# platform_designer_hps_system_hps_0_hps register map
Vendor: default_vendor.com; File version: 0.0
Registers are 32-bit, read-write, reset 0x0 unless marked. A register's access mark holds for its fields unless they carry their own. Offsets are from the block's base; [hi:lo] are bit positions; {n}, {i} and the like mark numbered series; 'fields as' and 'values as' point back to an identical list.

## usb0 (part 2 of 4) — Registers in the USB OTG Controller Module. Only the Core Global, Power and Clock Gating, Data FIFO Access, and Host Port registers can be accessedin both Host and Device modes. When the USB OTG Controller is operating in one mode, either Device or Host, the application must not access registers from the other mode. If an illegal access occurs, a Mode Mismatch interrupt is generated and reflected in the Core Interrupt register (GINTSTS.ModeMis). When the core switches from one mode to another, the registers in the new mode must be reprogrammed as they would be after a power-on reset. The register address map is fixed and does not depend on the module configuration (for example, how many endpoints are implemented). Host and Device mode registers occupy different addresses.
Base 0xFFB00000
Same registers: usb1 0xFFB40000
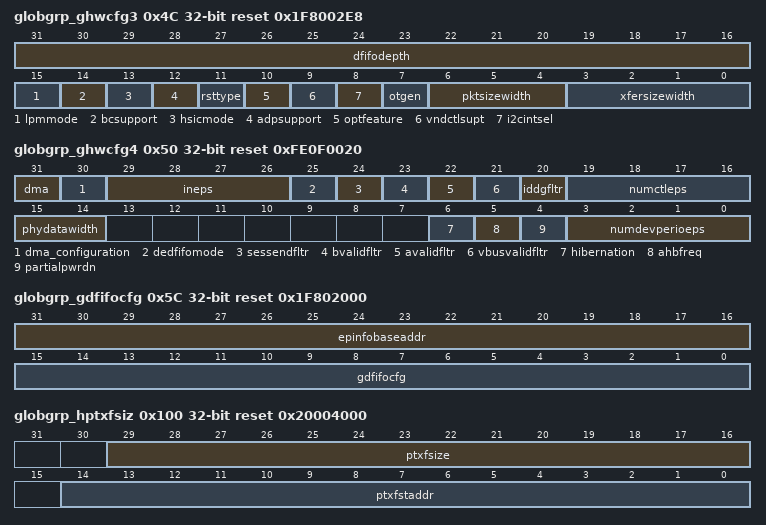
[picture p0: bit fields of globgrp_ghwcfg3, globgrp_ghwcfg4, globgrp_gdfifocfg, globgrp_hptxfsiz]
0x4C globgrp_ghwcfg3 ro reset 0x1F8002E8 — This register contains the configuration options.
  [31:16] dfifodepth — DFIFO Depth. This value is in terms of 35-bit words. Minimum value is 32 Maximum value is 8192
  [15] lpmmode — LPM Mode Enabled/Disabled.
    0=disabled
  [14] bcsupport — Battery Charger Support.
    0=disabled
  [13] hsicmode — Supports HSIC and Non-HSIC Modes.
    0=disabled
  [12] adpsupport — ADP logic support.
    1=enabled
  [11] rsttype — Defines what reset type is used in the core.
    0=enabled
  [10] optfeature — User ID register, GPIO interface ports, and SOF toggle and counter ports were removed.
    0=disabled
  [9] vndctlsupt — ULPI PHY internal registers can be accessed by software using register reads/writes to otg
    1=enabled
  [8] i2cintsel — I2C Interface not used.
    0=disabled
  [7] otgen — HNP and SRP Capable OTG (Device and Host)
    1=enabled
  [6:4] pktsizewidth
    {v}=bits{v+4} (v=0..6)
  [3:0] xfersizewidth — Width variable from 11 to 19 bits.
    {v}=width{v+11} (v=0..8)
0x50 globgrp_ghwcfg4 ro reset 0xFE0F0020 — This register contains the configuration options.
  [31] dma — Enable descriptor based scatter/gather DMA. When enabled, DMA operations will be serviced with descriptor based scatter/gather DMA
    1=enabled
  [30] dma_configuration — Selects bewteen scatter and nonscatter configuration
    0=nonscatter; 1=scatter
  [29:26] ineps — Number of Device Mode IN Endpoints Including Control.
    {v}=endpt{v+1} (v=0..15)
  [25] dedfifomode — Specifies whether Dedicated Transmit FIFOs should be enabled in device mode.
    1=enabled
  [24] sessendfltr — Specifies whether to add a filter on the session_end input from the PHY.
    0=disabled
  [23] bvalidfltr — Specifies whether to add a filter on the b_valid input from the PHY.
    0=disabled
  [22] avalidfltr — Specifies whether to add a filter on the b_valid input from the PHY.
    0=disabled
  [21] vbusvalidfltr — Vbus Valid Filter Enabled (VBusValidFltr) 0: No filter 1: Filter(coreConsultant parameter: OTG_EN_VBUSVALID_FILTER)
    0=disabled
  [20] iddgfltr — Specifies whether to add a filter on the iddig input from the PHY. This is not relevant since we only support ULPI and there is no iddig pin exposed to I/O pads.
    0=disabled
  [19:16] numctleps — Specifies the number of Device mode control endpoints in addition to control endpoint 0, which is always present. Range: 0-15.
    {v}=endpt{v} (v=0..15)
  [15:14] phydatawidth — Uses a ULPI interface only. Hence only 8-bit setting is relevant. This setting should not matter since UTMI is not enabled.
  [6] hibernation — Enables power saving mode hibernation.
    0=disabled
  [5] ahbfreq — When the AHB frequency is less than 60 MHz, 4-deep clock-domain crossing sink and source buffers are instantiated between the MAC and the Packet FIFO Controller (PFC); otherwise, two-deep buffers are sufficient.
    1=enabled
  [4] partialpwrdn — Specifies whether to enable power optimization.
    0=disabled
  [3:0] numdevperioeps — The maximum number of device IN operations is 16 active at any time including endpoint 0, which is always present. This parameter determines the number of device mode Tx FIFOs to be instantiated.
0x5C globgrp_gdfifocfg reset 0x1F802000 — Specifies whether Dedicated Transmit FIFOs should be enabled in device mode.
  [31:16] epinfobaseaddr — This field provides the start address of the EP info controller.
  [15:0] gdfifocfg — This field is for dynamic programming of the DFIFO Size. This value takes effect only when the application programs a non zero value to this register. The otg core does not have any corrective logic if the FIFO sizes are programmed incorrectly.
0x100 globgrp_hptxfsiz reset 0x20004000 — This register holds the size and the memory start address of the Periodic TxFIFO
  [29:16] ptxfsize — This value is in terms of 32-bit words. Minimum value is 16 Maximum value is 1024 The power-on reset value of this register is specified as the 1024.
  [14:0] ptxfstaddr — The power-on reset value of this register is the sum of the Largest Rx Data FIFO Depth and Largest Non-periodic Tx Data FIFO. Programmed values must not exceed the power-on value
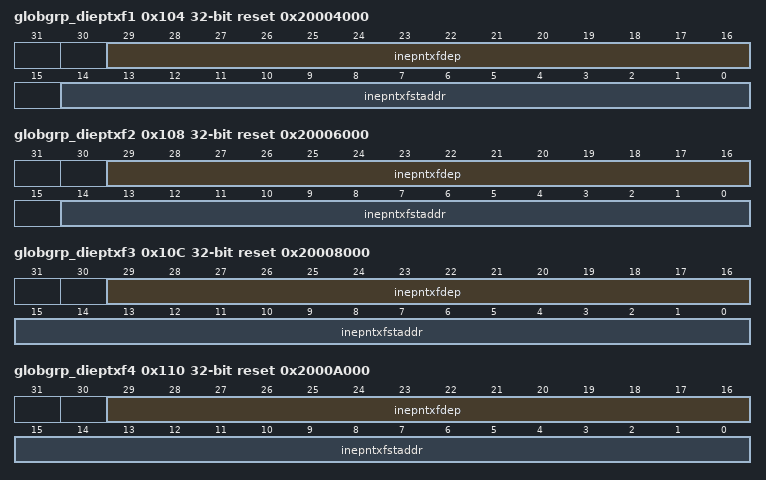
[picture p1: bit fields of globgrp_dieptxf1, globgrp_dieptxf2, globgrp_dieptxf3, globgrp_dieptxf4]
0x104 globgrp_dieptxf1 reset 0x20004000 — This register holds the size and memory start address of IN endpoint TxFIFOs implemented in Device mode. Each FIFO holds the data for one IN endpoint. This register is repeated for each instantiated IN endpoint FIFO. For IN endpoint FIFO 0 use GNPTXFSIZ register for programming the size and memory start address.
  [29:16] inepntxfdep — This value is in terms of 32-bit words. Minimum value is 16 Maximum value is 8192.
  [14:0] inepntxfstaddr — This field contains the memory start address for IN endpoint Transmit FIFO 1.
0x108 globgrp_dieptxf2 reset 0x20006000 — This register holds the size and memory start address of IN endpoint TxFIFOs implemented in Device mode. Each FIFO holds the data for one IN endpoint. This register is repeated for instantiated IN endpoint FIFO. For IN endpoint FIFO 0 use GNPTXFSIZ register for programming the size and memory start address.
  [29:16] inepntxfdep — This value is in terms of 32-bit words. Minimum value is 16 Maximum value is 8192
  [14:0] inepntxfstaddr — This field contains the memory start address for IN endpoint Transmit FIFO 2.
0x10C globgrp_dieptxf3 reset 0x20008000 — This register holds the size and memory start address of IN endpoint TxFIFOs implemented in Device mode. Each FIFO holds the data for one IN endpoint. This register is repeated for instantiated IN endpoint FIFO. For IN endpoint FIFO 0 use GNPTXFSIZ register for programming the size and memory start address.
  [29:16] inepntxfdep — This value is in terms of 32-bit words.Minimum value is 16Maximum value is 8192
  [15:0] inepntxfstaddr — This field contains the memory start address for IN endpoint Transmit FIFO 3.
0x110 globgrp_dieptxf4 reset 0x2000A000 — This register holds the size and memory start address of IN endpoint TxFIFOs implemented in Device mode. Each FIFO holds the data for one IN endpoint. This register is repeated for each instantiated IN endpoint FIFO. For IN endpoint FIFO 0 use GNPTXFSIZ register for programming the size and memory start address.
  [29:16] inepntxfdep — This value is in terms of 32-bit words. Minimum value is 16 Maximum value is 8192.
  [15:0] inepntxfstaddr — This field contains the memory start address for IN endpoint Transmit FIFO 4.
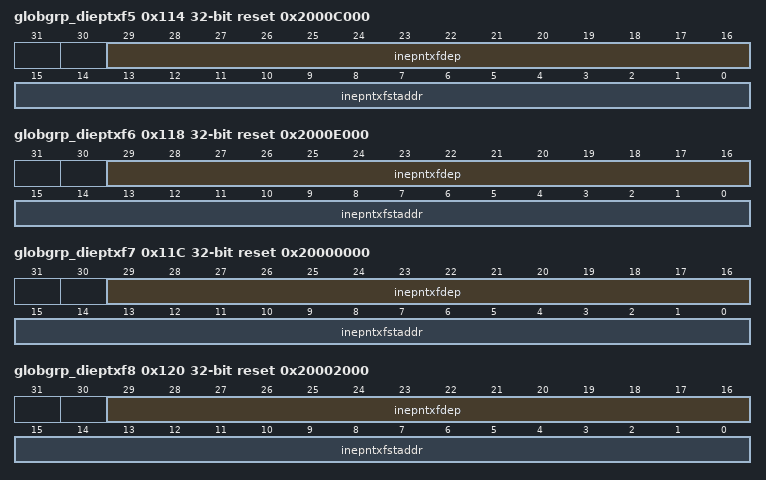
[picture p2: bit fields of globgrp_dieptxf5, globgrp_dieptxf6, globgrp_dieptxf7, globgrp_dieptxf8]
0x114 globgrp_dieptxf5 reset 0x2000C000 — This register holds the size and memory start address of IN endpoint TxFIFOs implemented in Device mode. Each FIFO holds the data for one IN endpoint. This register is repeated for each instantiated IN endpoint FIFO. For IN endpoint FIFO 0 use GNPTXFSIZ register for programming the size and memory start address.
  [29:16] inepntxfdep — This value is in terms of 32-bit words. Minimum value is 16 Maximum value is 8192.
  [15:0] inepntxfstaddr — This field contains the memory start address for IN endpoint Transmit FIFO 5.
0x118 globgrp_dieptxf6 reset 0x2000E000 — This register holds the size and memory start address of IN endpoint TxFIFOs implemented in Device mode. Each FIFO holds the data for one IN endpoint. This register is repeated for each instantiated IN endpoint FIFO. For IN endpoint FIFO 0 use GNPTXFSIZ register for programming the size and memory start address.
  [29:16] inepntxfdep — This value is in terms of 32-bit words. Minimum value is 16 Maximum value is 8192.
  [15:0] inepntxfstaddr — This field contains the memory start address for IN endpoint Transmit FIFO 6.
0x11C globgrp_dieptxf7 reset 0x20000000 — This register holds the size and memory start address of IN endpoint TxFIFOs implemented in Device mode. Each FIFO holds the data for one IN endpoint. This register is repeated for each instantiated IN endpoint FIFO. For IN endpoint FIFO 0 use GNPTXFSIZ register for programming the size and memory start address.
  [29:16] inepntxfdep — This value is in terms of 32-bit words. Minimum value is 16 Maximum value is 8192.
  [15:0] inepntxfstaddr — This field contains the memory start address for IN endpoint Transmit FIFO 7.
0x120 globgrp_dieptxf8 reset 0x20002000 — This register holds the size and memory start address of IN endpoint TxFIFOs implemented in Device mode. Each FIFO holds the data for one IN endpoint. This register is repeated for each instantiated IN endpoint FIFO. For IN endpoint FIFO 0 use GNPTXFSIZ register for programming the size and memory start address.
  [29:16] inepntxfdep — This value is in terms of 32-bit words. Minimum value is 16 Maximum value is 8192.
  [15:0] inepntxfstaddr — This field contains the memory start address for IN endpoint Transmit FIFO 8.
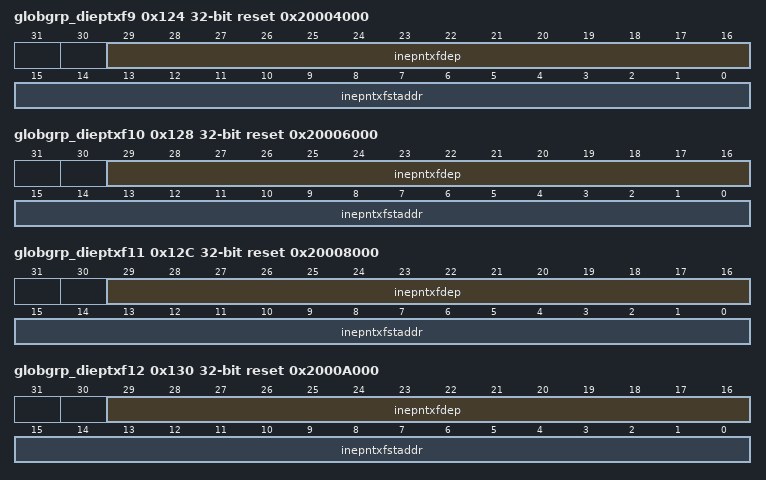
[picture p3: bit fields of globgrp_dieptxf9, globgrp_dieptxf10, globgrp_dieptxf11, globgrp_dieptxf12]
0x124 globgrp_dieptxf9 reset 0x20004000 — This register holds the size and memory start address of IN endpoint TxFIFOs implemented in Device mode. Each FIFO holds the data for one IN endpoint. This register is repeated for each instantiated IN endpoint FIFO. For IN endpoint FIFO 0 use GNPTXFSIZ register for programming the size and memory start address.
  [29:16] inepntxfdep — This value is in terms of 32-bit words. Minimum value is 16 Maximum value is 8192.
  [15:0] inepntxfstaddr — This field contains the memory start address for IN endpoint Transmit FIFO 9.
0x128 globgrp_dieptxf10 reset 0x20006000 — This register holds the size and memory start address of IN endpoint TxFIFOs implemented in Device mode. Each FIFO holds the data for one IN endpoint. This register is repeated for each instantiated IN endpoint FIFO. For IN endpoint FIFO 0 use GNPTXFSIZ register for programming the size and memory start address.
  [29:16] inepntxfdep — This value is in terms of 32-bit words. Minimum value is 16 Maximum value is 8192.
  [15:0] inepntxfstaddr — This field contains the memory start address for IN endpoint Transmit FIFO 10.
0x12C globgrp_dieptxf11 reset 0x20008000 — This register holds the size and memory start address of IN endpoint TxFIFOs implemented in Device mode. Each FIFO holds the data for one IN endpoint. This register is repeated for each instantiated IN endpoint FIFO. For IN endpoint FIFO 0 use GNPTXFSIZ register for programming the size and memory start address.
  [29:16] inepntxfdep — This value is in terms of 32-bit words. Minimum value is 16 Maximum value is 8192.
  [15:0] inepntxfstaddr — This field contains the memory start address for IN endpoint Transmit FIFO 11.
0x130 globgrp_dieptxf12 reset 0x2000A000 — This register holds the size and memory start address of IN endpoint TxFIFOs implemented in Device mode. Each FIFO holds the data for one IN endpoint. This register is repeated for each instantiated IN endpoint FIFO. For IN endpoint FIFO 0 use GNPTXFSIZ register for programming the size and memory start address.
  [29:16] inepntxfdep — This value is in terms of 32-bit words. Minimum value is 16 Maximum value is 8192.
  [15:0] inepntxfstaddr — This field contains the memory start address for IN endpoint Transmit FIFO 12.
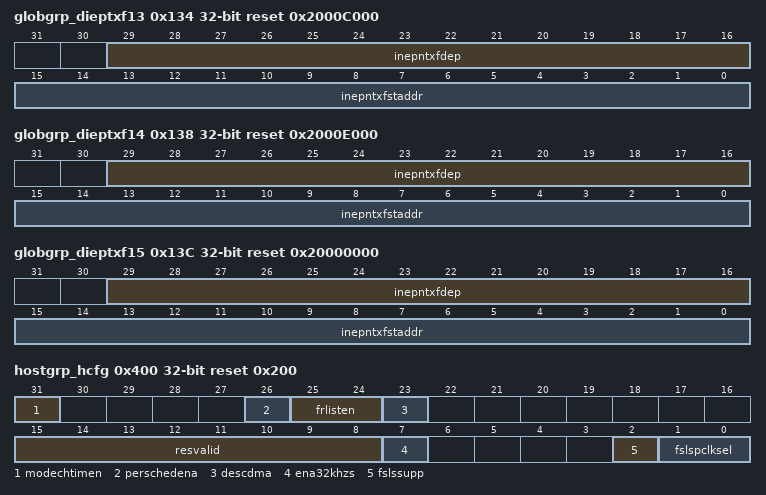
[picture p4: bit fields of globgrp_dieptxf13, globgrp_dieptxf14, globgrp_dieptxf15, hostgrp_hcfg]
0x134 globgrp_dieptxf13 reset 0x2000C000 — This register holds the size and memory start address of IN endpoint TxFIFOs implemented in Device mode. Each FIFO holds the data for one IN endpoint. This register is repeated for each instantiated IN endpoint FIFO. For IN endpoint FIFO 0 use GNPTXFSIZ register for programming the size and memory start address.
  [29:16] inepntxfdep — This value is in terms of 32-bit words. Minimum value is 16 Maximum value is 8192.
  [15:0] inepntxfstaddr — This field contains the memory start address for IN endpoint Transmit FIFO 13.
0x138 globgrp_dieptxf14 reset 0x2000E000 — This register holds the size and memory start address of IN endpoint TxFIFOs implemented in Device mode. Each FIFO holds the data for one IN endpoint. This register is repeated for each instantiated IN endpoint FIFO. For IN endpoint FIFO 0 use GNPTXFSIZ register for programming the size and memory start address.
  [29:16] inepntxfdep — This value is in terms of 32-bit words. Minimum value is 16 Maximum value is 8192.
  [15:0] inepntxfstaddr — This field contains the memory start address for IN endpoint Transmit FIFO 14.
0x13C globgrp_dieptxf15 reset 0x20000000 — This register holds the size and memory start address of IN endpoint TxFIFOs implemented in Device mode. Each FIFO holds the data for one IN endpoint. This register is repeated for each instantiated IN endpoint FIFO. For IN endpoint FIFO 0 use GNPTXFSIZ register for programming the size and memory start address.
  [29:16] inepntxfdep — This value is in terms of 32-bit words. Minimum value is 16 Maximum value is 8192.
  [15:0] inepntxfstaddr — This field contains the memory start address for IN endpoint Transmit FIFO 15.
0x400 hostgrp_hcfg reset 0x200 — Host Mode control. This register must be programmed every time the core changes to Host mode
  [31] modechtimen — This bit is used to enable or disable the host core to wait for 200 PHY clock cycles at the end of Resume to change the opmode signal to the PHY to 00 after Suspend or LPM.
    0=enabled; 1=disabled
  [26] perschedena — Applicable in Scatter/Gather DMA mode only. Enables periodic scheduling within the core. Initially, the bit is reset. The core will not process any periodic channels. As soon as this bit is set, the core will get ready to start scheduling periodic channels. In non Scatter/Gather DMA mode, this bit is reserved.
    0=disabled; 1=enabled
  [25:24] frlisten — The value in the register specifies the number of entries in the Frame list. This field is valid only in Scatter/Gather DMA mode.
    1=entry8; 2=entry16; 3=entry32
  [23] descdma — The application can set this bit during initialization to enable the Scatter/Gather DMA operation. This bit must be modified only once after a reset. The following combinations are available for programming: GAHBCFG.DMAEn=0,HCFG.DescDMA=0 => Slave mode GAHBCFG.DMAEn=0,HCFG.DescDMA=1 => InvalidGAHBCFG.DMAEn=1,HCFG.DescDMA=0 => Buffered DMA mode GAHBCFG.DMAEn=1,HCFG.DescDMA=1 => Scatter/Gather DMA mode
    0=disabled; 1=enabled
  [15:8] resvalid — This field is effective only when HCFG.Ena32KHzS is set. It will control the resume period when the core resumes from suspend. The core counts for ResValid number of clock cycles to detect a valid resume when this is set.
  [7] ena32khzs — This bit can only be set if the USB 1.1 Full-Speed Serial Transceiver Interface has been selected. If USB 1.1 Full-Speed Serial Transceiver Interface has not been selected, this bit must be zero. When the USB 1.1 Full-Speed Serial Transceiver Interface is chosen and this bit is set, the core expects the 48-MHz PHY clock to be switched to 32 KHz during a suspend.
    0=disabled; 1=enabled
  [2] fslssupp — The application uses this bit to control the core's enumeration speed. Using this bit, the application can make the core enumerate as a FS host, even If the connected device supports HS traffic. Do not make changes to this field after initial programming.
    0=hsfsls; 1=fsls
  [1:0] fslspclksel — When the core is in FS Host mode. The internal PHY clock is running at 30/60 MHZ for ULPI PHY Interfaces. The internal PHY clock is running at 48MHZ for 1.1 FS transceiver Interface When the core is in LS Host mode, the internal PHY clock is running at 30/60 MHZ for ULPI PHY Interfaces. The internal PHY clock is running at 6 MHZ and the external clock is running at 48MHZ. When you select a 6 MHz clock during LS Mode, you must do a soft reset for 1.1 FS transceiver Interface. * When Core in FS mode, the internal and external clocks have the same frequency. * When Core in LS mode, - If fslspclksel is 30/60 Mhz internal and external clocks have the same frequency. - If fslspclksel is 6Mhz the internal clock is divided by eight of external 48 MHz clock (utmifs_clk).
    0=clk3060; 1=clk48; 2=clk6
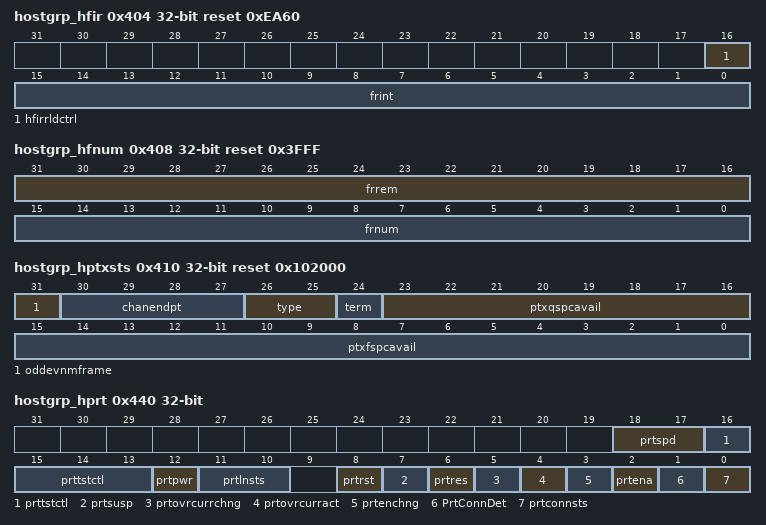
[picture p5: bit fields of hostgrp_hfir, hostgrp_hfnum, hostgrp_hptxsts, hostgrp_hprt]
0x404 hostgrp_hfir reset 0xEA60 — This register stores the frame interval information for the current speed to which the otg core has enumerated
  [16] hfirrldctrl — This bit allows dynamic reloading of the HFIR register during run time. 0x0 : The HFIR cannot be reloaded dynamically0x1: the HFIR can be dynamically reloaded during runtime. This bit needs to be programmed during initial configuration and its value should not be changed during runtime.
    0=disabled; 1=enabled
  [15:0] frint — The value that the application programs to this field specifies the interval between two consecutive SOFs (FS) or micro- SOFs (HS) or Keep-Alive tokens (HS). This field contains the number of PHY clocks that constitute the required frame interval. The Default value Set in this field for a FS operation when the PHY clock frequency is 60 MHz. The application can write a value to this register only after the Port Enable bit of the Host Port Control and Status register (HPRT.PrtEnaPort) has been Set. If no value is programmed, the core calculates the value based on the PHY clock specified in the FS/LS PHY Clock Select field of the Host Configuration register (HCFG.FSLSPclkSel). Do not change the value of this field after the initial configuration. 125 s * (PHY clock frequency for HS) 1 ms * (PHY clock frequency for FS/LS)
0x408 hostgrp_hfnum ro reset 0x3FFF — This register contains the free space information for the Periodic TxFIFO and the Periodic Transmit Request Queue
  [31:16] frrem — Indicates the amount of time remaining in the current microframe (HS) or Frame (FS/LS), in terms of PHY clocks. This field decrements on each PHY clock. When it reaches zero, this field is reloaded with the value in the Frame Interval register and a new SOF is transmitted on the USB.
  [15:0] frnum — This field increments when a new SOF is transmitted on the USB, and is reset to 0 when it reaches 0x3FFF. Reads Return the Frame number value.
    0=inactive; 1=active
0x410 hostgrp_hptxsts ro reset 0x102000 — This register contains the free space information for the Periodic TxFIFO and the Periodic Transmit Request Queue.
  [31] oddevnmframe — This indicates the odd/even micro frame that is currently being processes by the MAC.
    0=even; 1=odd
  [30:27] chanendpt — This indicates the channel endpoint number that is currently being processes by the MAC.
    {v}=endpt{v} (v=0..15)
  [26:25] type — This indicates the Entry in the Periodic Tx Request Queue that is currently being processes by the MAC.
    0=inout; 1=zerolngth; 2=csplit; 3=disable
  [24] term — Terminate last entry for selected channel/endpoint.
    0=inactive; 1=active
  [23:16] ptxqspcavail — Indicates the number of free locations available to be written in the Periodic Transmit Request Queue. This queue holds both IN and OUT requests. Others: Reserved
    0=full; {v}=free{v} (v=1..8)
  [15:0] ptxfspcavail — Indicates the number of free locations available to be written to in the Periodic TxFIFO. Values are in terms of 32-bit words 16h0: Periodic TxFIFO is full 16h1: 1 word available 16h2: 2 words available 16hn: n words available where n is 0 to 8192
0x414 hostgrp_haint ro — When a significant event occurs on a channel, the Host All Channels Interrupt register interrupts the application using the Host Channels Interrupt bit of the Core Interrupt register (GINTSTS.HChInt). There is one interrupt bit per channel, up to a maximum of 16 bits. Bits in this register are set and cleared when the application sets and clears bits in the corresponding Host Channel-n Interrupt register.
  [15:0] haint — One bit per channel: Bit 0 for Channel 0, bit 15 for Channel 15
0x418 hostgrp_haintmsk — The Host All Channel Interrupt Mask register works with the Host All Channel Interrupt register to interrupt the application when an event occurs on a channel. There is one interrupt mask bit per channel, up to a maximum of 16 bits.
  [15:0] haintmsk — One bit per channel: Bit 0 for channel 0, bit 15 for channel 15
    0=mask; 1=nomask
0x41C hostgrp_hflbaddr — This Register is valid only for Host mode Scatter-Gather DMA. Starting address of the Frame list. This register is used only for Isochronous and Interrupt Channels.
  [31:0] hflbaddr — This Register is valid only for Host mode Scatter-Gather DMA mode. Starting address of the Frame list. This register is used only for Isochronous and Interrupt Channels.
0x440 hostgrp_hprt — This register is available only in Host mode. Currently, the OTG Host supports only one port. A single register holds USB port-related information such as USB reset, enable, suspend, resume, connect status, and test mode for each port.The R_SS_WC bits in this register can trigger an interrupt to the application through the Host Port Interrupt bit of the Core Interrupt register (GINTSTS.PrtInt). On a Port Interrupt, the application must read this register and clear the bit that caused the interrupt. for the R_SS_WC bits, the application must write a 1 to the bit to clear the interrupt
  [18:17] prtspd ro — Indicates the speed of the device attached to this port.
    0=highspd; 1=fullspd; 2=lowspd
  [16:13] prttstctl — The application writes a nonzero value to this field to put the port into a Test mode, and the corresponding pattern is signaled on the port.
    0=disabled; 1=testj; 2=testk; 3=testsn; 4=testpm; 5=testfenb
  [12] prtpwr — The application uses this field to control power to this port, and the core can clear this bit on an over current condition.
    0=off; 1=on
  [11:10] prtlnsts ro — Indicates the current logic level USB data lines. Bit [10]: Logic level of D+ Bit [11]: Logic level of D-
    1=plusd; 2=minusd
  [8] prtrst — When the application sets this bit, a reset sequence is started on this port. The application must time the reset period and clear this bit after the reset sequence is complete. The application must leave this bit Set for at least a minimum duration mentioned below to start a reset on the port. The application can leave it Set for another 10 ms in addition to the required minimum duration, before clearing the bit, even though there is no maximum limit set by theUSB standard. This bit is cleared by the core even if there is no device connected to the Host. High speed: 50 ms Full speed/Low speed: 10 ms
    0=disabled; 1=enabled
  [7] prtsusp ro — The application sets this bit to put this port in Suspend mode. The core only stops sending SOFs when this is Set. To stop the PHY clock, the application must Set the Port Clock Stop bit, which asserts the suspend input pin of the PHY. The read value of this bit reflects the current suspend status of the port. This bit is cleared by the core after a remote wakeup signal is detected or the application sets the Port Reset bit or Port Resume bit in this register or the Resume/Remote Wakeup Detected Interrupt bit or Disconnect Detected Interrupt bit in the Core Interrupt register (GINTSTS.WkUpInt or GINTSTS.DisconnInt, respectively). This bit is cleared by the core even if there is no device connected to the Host.
    0=inactive; 1=active
  [6] prtres — The application sets this bit to drive resume signaling on the port. The core continues to drive the resume signal until the application clears this bit. If the core detects a USB remote wakeup sequence, as indicated by the Port Resume/Remote Wakeup Detected Interrupt bit of the Core Interrupt register (GINTSTS.WkUpInt), the core starts driving resume signaling without application intervention and clears this bit when it detects a disconnect condition. The read value of this bit indicates whether the core is currently drivingresume signaling. When LPM is enabled and the core is in the L1 (Sleep) state, setting this bit results in the following behavior: The core continues to drive the resume signal until a pre-determined time specified in the GLPMCFG.HIRD_Thres[3:0] field. If the core detects a USB remote wakeup sequence, as indicated by the Port L1 Resume/Remote L1 Wakeup Detected Interrupt bit of the Core Interrupt register (GINTSTS.L1WkUpInt), the core starts driving resume signaling without application intervention and clears this bit at the end of the resume. The read value of this bit indicates whether the core is currently driving resume signaling.
    0=noresume; 1=resume
  [5] prtovrcurrchng ro — The core sets this bit when the status of the PortOvercurrent Active bit (bit 4) in this register changes.This bit can be set only by the core and the application should write 1 to clear it
    0=inactive; 1=active
  [4] prtovrcurract ro — Indicates the overcurrent condition of the port. 0x0: No overcurrent condition 0x1: Overcurrent condition
    0=inactive; 1=active
  [3] prtenchng ro — The core sets this bit when the status of the Port Enable bit [2] of this register changes. This bit can be set only by the core and the application should write 1 to clear it.
    0=inactive; 1=active
  [2] prtena ro — A port is enabled only by the core after a reset sequence, and is disabled by an overcurrent condition, a disconnect condition, or by the application clearing this bit. The application cannot Set this bit by a register write. It can only clear it to disable the port by writing 1. This bit does not trigger any interrupt to the application.
    0=disabled; 1=enabled
  [1] PrtConnDet ro — The core sets this bit when a device connection is detected to trigger an interrupt to the application using the Host Port Interrupt bit of the Core Interrupt register (GINTSTS.PrtInt). This bit can be set only by the core and the application should write 1 to clear it.The application must write a 1 to this bit to clear the interrupt.
    0=active; 1=inactive
  [0] prtconnsts ro — Defines whether port is attached.
    0=notattached; 1=attached
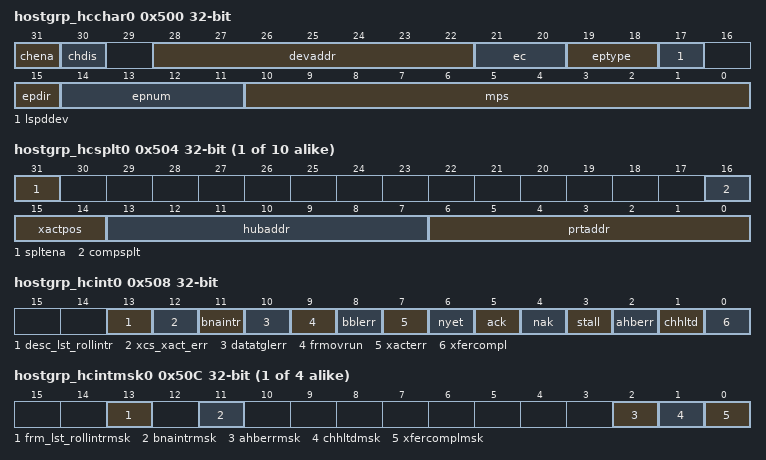
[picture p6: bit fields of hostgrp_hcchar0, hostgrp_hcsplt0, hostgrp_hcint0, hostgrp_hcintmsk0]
0x500 hostgrp_hcchar0 — Channel_number: 0.
  [31] chena ro — When Scatter/Gather mode is disabled. This field is set by the application and cleared by the OTG host.
    0=notready; 1=ready
  [30] chdis ro — The application sets this bit to stop transmitting/receiving data on a channel, even before the transfer for that channel is complete. The application must wait for the Channel Disabled interrupt before treating the channel as disabled.
    0=inactive; 1=active
  [28:22] devaddr — This field selects the specific device serving as the data source or sink.
  [21:20] ec — When the Split Enable bit of the Host Channel-n Split Control register (HCSPLTn.SpltEna) is reset (0), this field indicates to the host the number of transactions that must be executed per microframe for this periodic endpoint. for non periodic transfers, this field is used only in DMA mode, and specifies the number packets to be fetched for this channel before the internal DMA engine changes arbitration. When HCSPLTn.SpltEna is Set (1'b1), this field indicates the number of immediate retries to be performed for a periodic split transactions on transaction errors. This field must be Set to at least 2'b01.
    1=transone; 2=transtwo; 3=transthree
  [19:18] eptype — Indicates the transfer type selected.
    0=ctrl; 1=isoc; 2=bulk; 3=interr
  [17] lspddev — This field is Set by the application to indicate that this channel is communicating to a low-speed device. The application must program this bit when a low speed device is connected to the host through an FS HUB. The HS OTG Host core uses this field to drive the XCVR_SELECT signal to 0x3 while communicating to the LS Device through the FS hub. In a peer to peer setup, the HS OTG Host core ignores this bit even if it is set by the application software.
    0=nonlowspeed; 1=lowspeed
  [15] epdir — Indicates whether the transaction is IN or OUT.
    0=outdir; 1=indir
  [14:11] epnum — Indicates the endpoint number on the device serving as the data source or sink.
    {v}=endpt{v} (v=0..15)
  [10:0] mps — Indicates the maximum packet size of the associated endpoint.
{0x504+0x20*i} hostgrp_hcsplt{i} (i=0..9) — Channel_number {i}
  [31] spltena — The application sets this field to indicate that this channel is enabled to perform split transactions.
    0=disabled; 1=enabled
  [16] compsplt — The application sets this field to request the OTG host to perform a complete split transaction.
    0=nosplit; 1=split
  [15:14] xactpos — This field is used to determine whether to send all, first, middle, or last payloads with each OUT transaction.
    0=middle; 1=end; 2=begin; 3=all
  [13:7] hubaddr — This field holds the device address of the transaction translator's hub.
  [6:0] prtaddr — This field is the port number of the recipient transactiontranslator.
0x508 hostgrp_hcint0 ro — This register indicates the status of a channel with respect to USB- and AHB-related events. The application must read this register when the Host Channels Interrupt bit of the Core Interrupt register (GINTSTS.HChInt) is set. Before the application can read this register, it must first read the Host All Channels Interrupt (HAINT) register to get the exact channel number for the Host Channel-n Interrupt register. The application must clear the appropriate bit in this register to clear the corresponding bits in the HAINT and GINTSTS registers.
  [13] desc_lst_rollintr — Descriptor rollover interrupt (DESC_LST_ROLLIntr)This bit is valid only when Scatter/Gather DMA mode is enabled. The core sets this bit when the corresponding channel's descriptor list rolls over. for non Scatter/Gather DMA mode, this bit is reserved.
    0=inactive; 1=active
  [12] xcs_xact_err — This bit is valid only when Scatter/Gather DMA mode is enabled. The core sets this bit when 3 consecutive transaction errors occurred on the USB bus. XCS_XACT_ERR will not be generated for Isochronous channels.for non Scatter/Gather DMA mode, this bit is reserved.
    0=inactive; 1=acvtive
  [11] bnaintr — This bit is valid only when Scatter/Gather DMA mode is enabled. The core generates this interrupt when the descriptor accessed is not ready for the Core to process. BNA will not be generated for Isochronous channels. for non Scatter/Gather DMA mode, this bit is reserved.
    0=inactive; 1=active
  [10] datatglerr — This bit can be set only by the core and the application should write 1 to clear it. In Scatter/Gather DMA mode, the interrupt due to this bit is masked in the core.
    0=inactive; 1=active
  [9] frmovrun — In Scatter/Gather DMA mode, the interrupt due to this bit is masked in the core. This bit can be set only by the core and the application should write 1 to clear it.
    0=inactive; 1=active
  [8] bblerr — In Scatter/Gather DMA mode, the interrupt due to this bit is masked in the core..This bit can be set only by the core and the application should write 1 to clear it.
    0=inactive; 1=active
  [7] xacterr — Indicates one of the following errors occurred on the USB.-CRC check failure -Timeout -Bit stuff error -False EOP In Scatter/Gather DMA mode, the interrupt due to this bit is masked in the core. This bit can be set only by the core and the application should write 1 to clear it.
    0=inactive; 1=active
  [6] nyet — In Scatter/Gather DMA mode, the interrupt due to this bit is masked in the core.This bit can be set only by the core and the application should write 1 to clear it.
    0=inactive; 1=active
  [5] ack — In Scatter/Gather DMA mode, the interrupt due to this bit is masked in the core. This bit can be set only by the core and the application should write 1 to clear it.
    0=inactive; 1=active
  [4] nak — In Scatter/Gather DMA mode, the interrupt due to this bit is masked in the core.This bit can be set only by the core and the application should write 1 to clear it.
    0=inactive; 1=active
  [3] stall — In Scatter/Gather DMA mode, the interrupt due to this bit is masked in the core. This bit can be set only by the core and the application should write 1 to clear it.
    0=inactive; 1=active
  [2] ahberr — This is generated only in Internal DMA mode when there is an AHB error during AHB read/write. The application can read the corresponding channel's DMA address register to get the error address.
    0=inactive; 1=active
  [1] chhltd — In non Scatter/Gather DMA mode, it indicates the transfer completed abnormally either because of any USB transaction error or in response to disable request by the application or because of a completed transfer. In Scatter/gather DMA mode, this indicates that transfer completed due to any of the following . EOL being set in descriptor . AHB error . Excessive transaction errors . Babble . Stall
    0=inactive; 1=active
  [0] xfercompl — Transfer completed normally without any errors. This bit can be set only by the core and the application should write 1 to clear it.
    0=inactive; 1=active
{0x50C+0x20*i} hostgrp_hcintmsk{i} (i=0..3) — This register reflects the mask for each channel status described in the previous section.
  [all] fields
    0=mask; 1=nomask
  [13] frm_lst_rollintrmsk — This bit is valid only when Scatter/Gather DMA mode is enabled.
  [11] bnaintrmsk — This bit is valid only when Scatter/Gather DMA mode is enabled.
  [2] ahberrmsk — In scatter/gather DMA mode for host, interrupts will not be generated due to the corresponding bits set in HCINTn.
  [1] chhltdmsk — Channel Halted.
  [0] xfercomplmsk — Transfer complete.
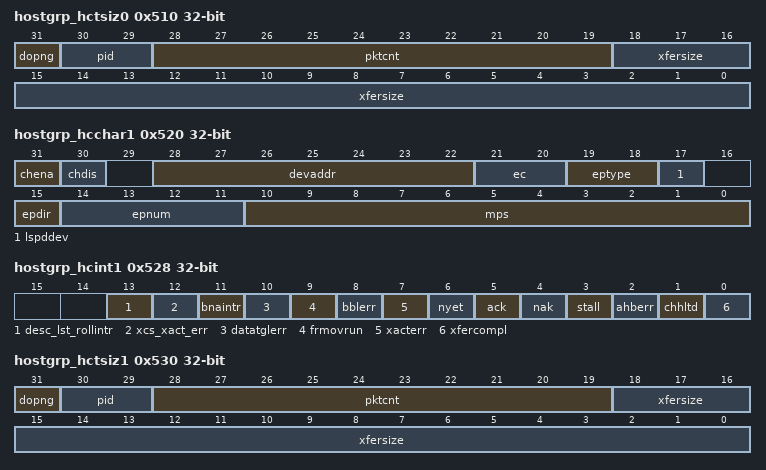
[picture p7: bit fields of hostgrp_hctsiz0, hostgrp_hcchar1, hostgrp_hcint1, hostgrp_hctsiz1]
0x510 hostgrp_hctsiz0 — Buffer DMA Mode
  [31] dopng — This bit is used only for OUT transfers.Setting this field to 1 directs the host to do PING protocol. Do not Set this bit for IN transfers. If this bit is set for IN transfers it disables the channel.
    0=noping; 1=ping
  [30:29] pid — The application programs this field with the type of PID to use forthe initial transaction. The host maintains this field for the rest of the transfer.
    0=data0; 1=data2; 2=data1; 3=mdata
  [28:19] pktcnt — This field is programmed by the application with the expected number of packets to be transmitted (OUT) or received (IN). The host decrements this count on every successful transmission or reception of an OUT/IN packet. Once this count reaches zero, the application is interrupted to indicate normal completion. The width of this counter is specified as 10 bits.
  [18:0] xfersize — For an OUT, this field is the number of data bytes the host sends during the transfer. for an IN, this field is the buffer size that the application has Reserved for the transfer. The application is expected to program this field as an integer multiple of the maximum packet size for IN transactions (periodic and non-periodic).The width of this counter is specified as 19 bits.
{0x514+0x20*i} hostgrp_hcdma{i} (i=0..15) — This register is used by the OTG host in the internal DMA mode to maintain the current buffer pointer for IN/OUT transactions. The starting DMA address must be DWORD-aligned.
  [31:0] hcdma{i} — Non-Isochronous: This field holds the start address of the 512 bytes page. The first descriptor in the list should be located in this address. The first descriptor may be or may not be ready. The core starts processing the list from the CTD value. This field holds the address of the 2*(nTD+1) bytes of locations in which the isochronous descriptors are present where N is based on nTD as per Table below [31:N] Base Address [N-1:3] Offset [2:0] 000 HS ISOC FS ISOC nTD N nTD N 7 6 1 4 15 7 3 5 31 8 7 6 63 9 15 7 127 10 31 8 255 11 63 9 [N-1:3] (Isoc):[8:3] (Non Isoc): Current Transfer Desc(CTD): Non Isochronous: This value is in terms of number of descriptors. The values can be from 0 to 63. 0 - 1 descriptor. 63 - 64 descriptors. This field indicates the current descriptor processed in the list. This field is updated both by application and the core. for example, if the application enables the channel after programming CTD=5, then the core will start processing the 6th descriptor. The address is obtained by adding a value of (8bytes*5=) 40(decimal) to DMAAddr. Isochronous: CTD for isochronous is based on the current frame/microframe value. Need to be set to zero by application.
{0x518+0x20*i} hostgrp_hcdmab{i} (i=0..15) — These registers are present only in case of Scatter/Gather DMA. These registers are implemented in RAM instead of flop-based implementation. Holds the current buffer address. This register is updated as and when the data transfer for the corresponding end point is in progress. This register is present only in Scatter/Gather DMA mode. Otherwise this field is reserved.
0x520 hostgrp_hcchar1 — Host Channel 1 Characteristics Register
  [31] chena ro — When Scatter/Gather mode is disabled This field is set by the application and cleared by the OTG host. 0: Channel disabled 1: Channel enabled When Scatter/Gather mode is enabled.
    0=inactive; 1=active
  [30] chdis ro — The application sets this bit to stop transmitting/receiving data on a channel, even before the transfer for that channel is complete. The application must wait for the Channel Disabled interrupt before treating the channel as disabled.
    0=inactive; 1=active
  [28:22] devaddr — This field selects the specific device serving as the data source or sink.
  [21:20] ec — When the Split Enable bit of the Host Channel-n Split Control register (HCSPLTn.SpltEna) is reset (0), this field indicates to the host the number of transactions that must be executed per microframe for this periodic endpoint. for non periodic transfers, this field is used only in DMA mode, and specifies the number packets to be fetched for this channel before the internal DMA engine changes arbitration. When HCSPLTn.SpltEna is Set (1), this field indicates the number of immediate retries to be performed for a periodic split transactions on transaction errors. This field must be set to at least 1.
    1=transone; 2=transtwo; 3=transthree
  [19:18] eptype — Indicates the transfer type selected.
    0=ctrl; 1=isoc; 2=bulk; 3=interr
  [17] lspddev — This field is set by the application to indicate that this channel is communicating to a low-speed device. The application must program this bit when a low speed device is connected to the host through an FS HUB. The HS OTG Host core uses this field to drive the XCVR_SELECT signal to 0x3 while communicating to the LS Device through the FS hub. In a peer to peer setup, the HS OTG Host core ignores this bit even if it is set by the application software
    0=disabled; 1=enabled
  [15] epdir — Indicates whether the transaction is IN or OUT.
    0=out; 1=in
  [14:11] epnum — Indicates the endpoint number on the device serving as the data source or sink.
    {v}=endpt{v} (v=0..15)
  [10:0] mps — Indicates the maximum packet size of the associated endpoint.
0x528 hostgrp_hcint1 ro — This register indicates the status of a channel with respect to USB- and AHB-related events. The application must read this register when the Host Channels Interrupt bit of the Core Interrupt register (GINTSTS.HChInt) is set. Before the application can read this register, it must first read the Host All Channels Interrupt (HAINT) register to get the exact channel number for the Host Channel-n Interrupt register. The application must clear the appropriate bit in this register to clear the corresponding bits in the HAINT and GINTSTS registers.
  fields as hostgrp_hcint0
0x530 hostgrp_hctsiz1 — Buffer DMA Mode
  [31] dopng — This bit is used only for OUT transfers.Setting this field to 1 directs the host to do PING protocol. Do not Set this bit for IN transfers. If this bit is set for IN transfers it disables the channel.
    0=noping; 1=ping
  [30:29] pid — The application programs this field with the type of PID to use forthe initial transaction. The host maintains this field for the rest of the transfer.
    0=data0; 1=data2; 2=data1; 3=mdata
  [28:19] pktcnt — This field is programmed by the application with the expected number of packets to be transmitted (OUT) or received (IN). The host decrements this count on every successful transmission or reception of an OUT/IN packet. Once this count reaches zero, the application is interrupted to indicate normal completion. The width of this counter is specified as 10 bits.
  [18:0] xfersize — for an OUT, this field is the number of data bytes the host sends during the transfer. for an IN, this field is the buffer size that the application has Reserved for the transfer. The application is expected to program this field as an integer multiple of the maximum packet size for IN transactions (periodic and non-periodic).The width of this counter is specified as 19 bits.
